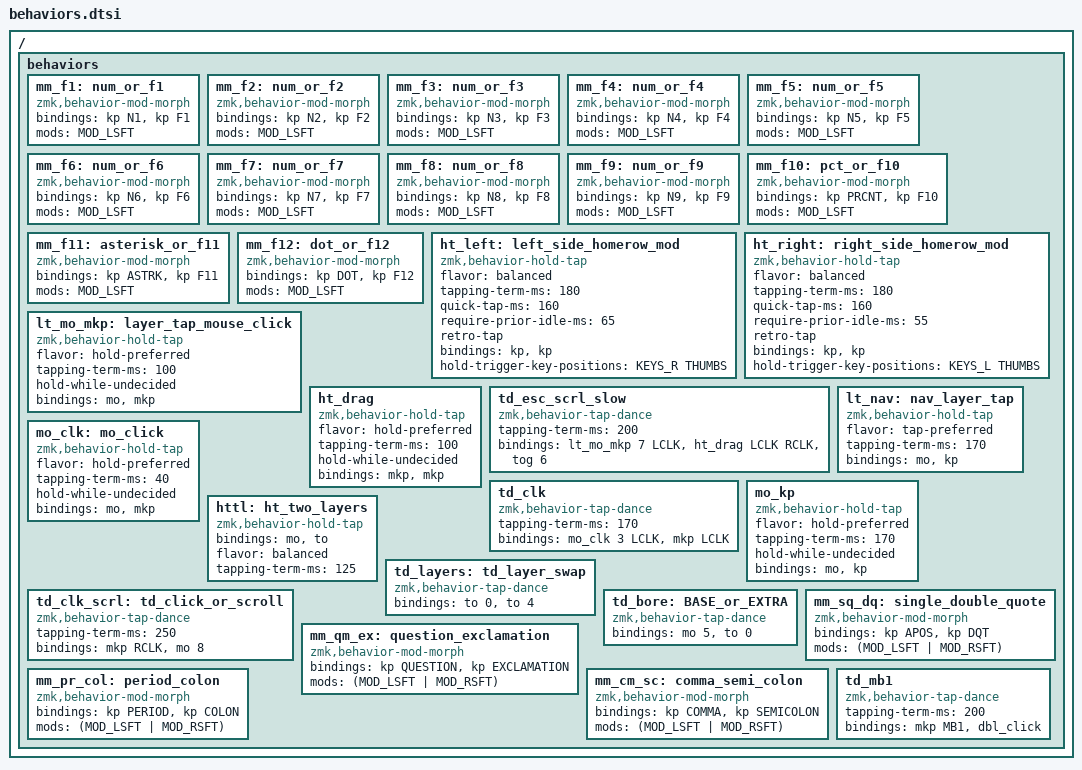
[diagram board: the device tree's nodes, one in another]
#define KEYS_L 0 1 2 3 4 5 12 13 14 15 16 17 24 25 26 27 28 29 36 37 38 19 20 21 22  // Left-hand keys.
#define KEYS_R 6 7 8 9 10 11 18 19 20 21 22 23 30 31 32 33 34 35 39 40 16 15 14 13  // Right-hand keys.
#define THUMBS 36 37 38 39 40  // Thumb keys.

/ {
    behaviors {
        // ht_num_func: homerow_mod {
        //     compatible = "zmk,behavior-hold-tap";
        //     #binding-cells = <2>;
        //     flavor = "tap-preferred";
        //     tapping-term-ms = <260>; // triggers the hold behavior when the tapping-term-ms has expired
        //     quick-tap-ms = <220>; // If you press a tapped hold-tap again within quick-tap-ms milliseconds of the first press, it will always trigger the tap behavior.
        //     require-prior-idle-ms = <185>; // like quick-tap-ms however it will apply for any non-modifier key pressed before it
        //     bindings = <&kp>, <&kp>;  // hold, tap
        // };

        mm_f1: num_or_f1 {
            compatible    = "zmk,behavior-mod-morph";
            #binding-cells = <0>;
            bindings      = <&kp N1>, <&kp F1>;
            mods          = <MOD_LSFT>;
        };

        mm_f2: num_or_f2 {
            compatible    = "zmk,behavior-mod-morph";
            #binding-cells = <0>;
            bindings      = <&kp N2>, <&kp F2>;
            mods          = <MOD_LSFT>;
        };

        mm_f3: num_or_f3 {
            compatible    = "zmk,behavior-mod-morph";
            #binding-cells = <0>;
            bindings      = <&kp N3>, <&kp F3>;
            mods          = <MOD_LSFT>;
        };

        mm_f4: num_or_f4 {
            compatible    = "zmk,behavior-mod-morph";
            #binding-cells = <0>;
            bindings      = <&kp N4>, <&kp F4>;
            mods          = <MOD_LSFT>;
        };

        mm_f5: num_or_f5 {
            compatible    = "zmk,behavior-mod-morph";
            #binding-cells = <0>;
            bindings      = <&kp N5>, <&kp F5>;
            mods          = <MOD_LSFT>;
        };

        mm_f6: num_or_f6 {
            compatible    = "zmk,behavior-mod-morph";
            #binding-cells = <0>;
            bindings      = <&kp N6>, <&kp F6>;
            mods          = <MOD_LSFT>;
        };

        mm_f7: num_or_f7 {
            compatible    = "zmk,behavior-mod-morph";
            #binding-cells = <0>;
            bindings      = <&kp N7>, <&kp F7>;
            mods          = <MOD_LSFT>;
        };

        mm_f8: num_or_f8 {
            compatible    = "zmk,behavior-mod-morph";
            #binding-cells = <0>;
            bindings      = <&kp N8>, <&kp F8>;
            mods          = <MOD_LSFT>;
        };

        mm_f9: num_or_f9 {
            compatible    = "zmk,behavior-mod-morph";
            #binding-cells = <0>;
            bindings      = <&kp N9>, <&kp F9>;
            mods          = <MOD_LSFT>;
        };

        mm_f10: pct_or_f10 {
            compatible    = "zmk,behavior-mod-morph";
            #binding-cells = <0>;
            bindings      = <&kp PRCNT>, <&kp F10>;
            mods          = <MOD_LSFT>;
        };

        mm_f11: asterisk_or_f11 {
            compatible    = "zmk,behavior-mod-morph";
            #binding-cells = <0>;
            bindings      = <&kp ASTRK>, <&kp F11>;
            mods          = <MOD_LSFT>;
        };

        mm_f12: dot_or_f12 {
            compatible    = "zmk,behavior-mod-morph";
            #binding-cells = <0>;
            bindings      = <&kp DOT>, <&kp F12>;
            mods          = <MOD_LSFT>;
        };

        // Left-hand HRM
        ht_left: left_side_homerow_mod {
            compatible = "zmk,behavior-hold-tap";
            #binding-cells = <2>;
            flavor = "balanced";
            tapping-term-ms = <180>;
            quick-tap-ms = <160>;
            require-prior-idle-ms = <65>;
            retro-tap;
            bindings = <&kp>, <&kp>;
            hold-trigger-key-positions = <KEYS_R THUMBS>;
        };

        // Right-hand HRM
        ht_right: right_side_homerow_mod {
            compatible = "zmk,behavior-hold-tap";
            #binding-cells = <2>;
            flavor = "balanced";
            tapping-term-ms = <180>;
            quick-tap-ms = <160>;
            require-prior-idle-ms = <55>;
            retro-tap;
            bindings = <&kp>, <&kp>;
            hold-trigger-key-positions = <KEYS_L THUMBS>;
        };

        lt_mo_mkp: layer_tap_mouse_click {
            compatible = "zmk,behavior-hold-tap";
            #binding-cells = <2>;
            flavor = "hold-preferred";
            tapping-term-ms = <100>;
            hold-while-undecided;
            bindings = <&mo>, <&mkp>;
        };

        ht_drag: ht_drag {
            compatible = "zmk,behavior-hold-tap";
            #binding-cells = <2>;
            flavor = "hold-preferred";
            tapping-term-ms = <100>;
            hold-while-undecided;
            bindings = <&mkp>, <&mkp>; // hold=mouse button held, tap=mouse button tap
        };

        td_esc_scrl_slow: td_esc_scrl_slow {
            compatible = "zmk,behavior-tap-dance";
            #binding-cells = <0>;
            tapping-term-ms = <200>;
            bindings = <&lt_mo_mkp 7 LCLK>, <&ht_drag LCLK RCLK>, <&tog 6>; // tap=left click, hold=scroll layer, double-tap=right click, double-tap+hold=hold left click (drag), triple-tap=toggle slow layer (speed)
        };

        lt_nav: nav_layer_tap {
            compatible = "zmk,behavior-hold-tap";
            #binding-cells = <2>;
            flavor = "tap-preferred";
            tapping-term-ms = <170>;
            bindings = <&mo>, <&kp>;
        };

        mo_clk: mo_click {
            compatible = "zmk,behavior-hold-tap";
            #binding-cells = <2>;
            flavor = "hold-preferred";
            tapping-term-ms = <40>;
            hold-while-undecided;
            bindings = <&mo>, <&mkp>;
        };

        td_clk: td_clk {
            compatible = "zmk,behavior-tap-dance";
            #binding-cells = <0>;
            tapping-term-ms = <170>;
            bindings = <&mo_clk 3 LCLK>, <&mkp LCLK>; // hold, tap, double_tap
        };

        mo_kp: mo_kp {
            compatible = "zmk,behavior-hold-tap";
            #binding-cells = <2>;
            flavor       = "hold-preferred";
            tapping-term-ms = <170>;
            hold-while-undecided;
            bindings = <&mo>, <&kp>;
        };

        httl: ht_two_layers {
            compatible = "zmk,behavior-hold-tap";
            bindings = <&mo>, <&to>;
            #binding-cells = <2>;
            flavor = "balanced";
            tapping-term-ms = <125>;
        };

        td_layers: td_layer_swap {
            compatible = "zmk,behavior-tap-dance";
            #binding-cells = <0>;
            bindings = <&to 0>, <&to 4>; // tap, double_tap
        };

        td_clk_scrl: td_click_or_scroll {
            compatible = "zmk,behavior-tap-dance";
            #binding-cells = <0>;
            tapping-term-ms = <250>;
            bindings = <&mkp RCLK>, <&mo 8>;  // tap/hold, double_tap
        };

        td_bore: BASE_or_EXTRA {
            compatible = "zmk,behavior-tap-dance";
            #binding-cells = <0>;
            bindings = <&mo 5>, <&to 0>;
        };

        mm_qm_ex: question_exclamation {
            compatible    = "zmk,behavior-mod-morph";
            #binding-cells = <0>;
            bindings      = <&kp QUESTION>, <&kp EXCLAMATION>;
            mods          = <(MOD_LSFT | MOD_RSFT)>;
        };

        mm_sq_dq: single_double_quote {
            compatible    = "zmk,behavior-mod-morph";
            #binding-cells = <0>;
            bindings      = <&kp APOS>, <&kp DQT>;
            mods          = <(MOD_LSFT | MOD_RSFT)>;
        };

        mm_pr_col: period_colon {
            compatible    = "zmk,behavior-mod-morph";
            #binding-cells = <0>;
            bindings      = <&kp PERIOD>, <&kp COLON>;
            mods          = <(MOD_LSFT | MOD_RSFT)>;
        };

        mm_cm_sc: comma_semi_colon {
            compatible    = "zmk,behavior-mod-morph";
            #binding-cells = <0>;
            bindings      = <&kp COMMA>, <&kp SEMICOLON>;
            mods          = <(MOD_LSFT | MOD_RSFT)>;
        };

        td_mb1: td_mb1 {
            compatible = "zmk,behavior-tap-dance";
            #binding-cells = <0>;
            tapping-term-ms = <200>;
            bindings = <&mkp MB1>, <&dbl_click>; // tap=left click, double tap=double click
        };
    };
};
